# Template register map
Vendor: VendorName Co.Ltd; Series: SeriesName; File version: 1.2
CPU: CM7 r0p1, little endian, MPU, FPU, 4 interrupt priority bits
Registers are 32-bit, read-write, no defined reset value unless marked. A register's access mark holds for its fields unless they carry their own. Offsets are from the block's base; [hi:lo] are bit positions; {n}, {i} and the like mark numbered series.

## DCC1 — Dual-Clock Comparator
Base 0x40059000
Same registers: DCC2 0x4006B000, DCC3 0x4006C000
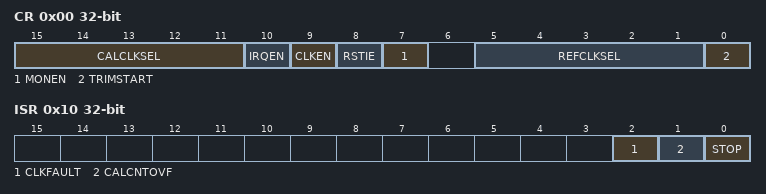
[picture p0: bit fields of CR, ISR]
0x00 CR — DCC config register
  [15:11] CALCLKSEL — DCC CALCLKSEL[4:0] bit: selection of clock source to be monitored
  [10] IRQEN — DCC IRQEN bit: interrupt enable
  [9] CLKEN — DCC CLKEN bit: clock enable
  [8] RSTIE — DCC RSTIE bit: reset or interrupt mode
  [7] MONEN — DCC MONEN bit: monitor mode enable
  [5:1] REFCLKSEL — DCC REFCLKSEL[4:0] bit: reference clock select
  [0] TRIMSTART — DCC TRIMSTART bit: soft monitor start
0x04 REFCON — DCC reference counter initial value config register
  [31:0] RCNTVAL — DCC RCNTVAL[31:0] bit: reference counter initial value
0x08 REFCNT ro — DCC reference counter value register
  [31:0] REFCNT — DCC REFCNT[31:0] bit: reference counter value
0x0C CALCNT ro — DCC calibrate counter value register
  [31:0] CALCNT — DCC CALCNT[31:0] bit: calibrated counter value
0x10 ISR ro — DCC interrupt flag register
  [2] CLKFAULT — DCC CLKFAULT bit: clock monitor fault flag
  [1] CALCNTOVF — DCC CALCNTOVF bit: calibration counter overflow flag
  [0] STOP — DCC STOP bit: reference counter stop flag
0x14 ICR wo — DCC interrupt flag clear register
  [2] CLKFAULT — DCC CLKFAULT bit: clear CLK_FAULT fault falg
0x1C HTCR — DCC clock monintor higher threshold comparison register
  [31:0] HTCR — DCC HTCR[31:0] bit: higher threshold compare
0x20 LTCR — DCC clock monintor lower threshold comparison register
  [31:0] LTCR — DCC LTCR[31:0] bit: low threshold compare

## DMAMUX1 — Direct Memory Access Multiplexer 1
Base 0x400B4000
Same registers: DMAMUX2 0x40093000
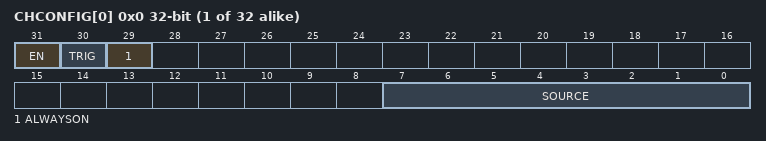
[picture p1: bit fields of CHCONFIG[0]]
{0x0+4i} CHCONFIG[{i}] (i=0..31) — Grouping of CHCONFIG
  [31] EN — DMAMUX EN bit: DMA mux channel enable
  [30] TRIG — DMAMUX TRIG bit: DMA channel trigger enable
  [29] ALWAYSON — DMAMUX ALWAYSON bit: DMA channel always enable
  [7:0] SOURCE — DMAMUX SOURCE[7:0] bit: DMA channel source

## EXTI — Extended Interrupt And Event Controller
Base 0x400C4000
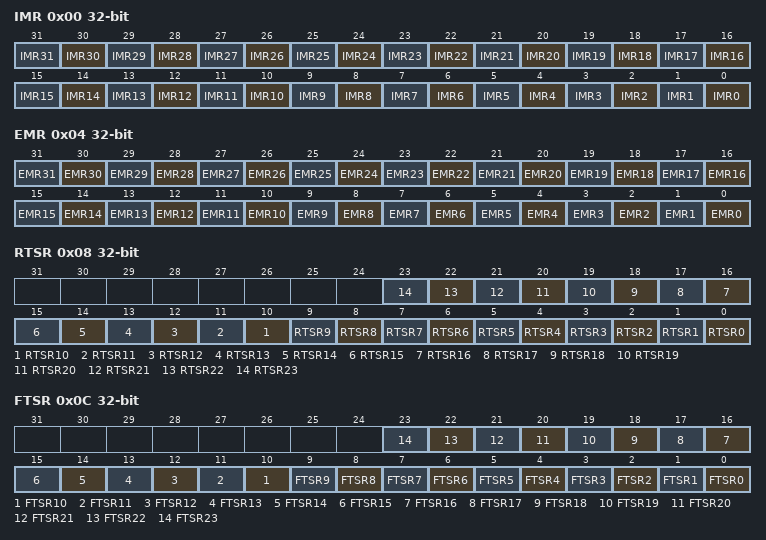
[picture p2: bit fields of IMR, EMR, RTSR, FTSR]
0x00 IMR — EXTI interrupt masking register
  [n] IMR{n} (n=24..31) — EXTI IMR{n} bit: direct event input {n}'s interrupt wakeup mask
  [n] IMR{n} (n=0..23) — EXTI IMR{n} bit: configurable event input {n}'s interrupt wakeup mask
0x04 EMR — EXTI event masking register
  [n] EMR{n} (n=24..31) — EXTI EMR{n} bit: direct event input {n}'s event wakeup mask
  [n] EMR{n} (n=0..23) — EXTI EMR{n} bit: configurable event input {n}'s event wakeup mask
0x08 RTSR — EXTI rising edge trigger selection register
  [n] RTSR{n} (n=0..23) — EXTI RTSR{n} bit: configurable event input {n}'s rising edge trigger configuration
0x0C FTSR — EXTI falling edge trigger selection register
  [n] FTSR{n} (n=0..23) — EXTI FTSR{n} bit: configurable event input {n}'s falling edge trigger configuration
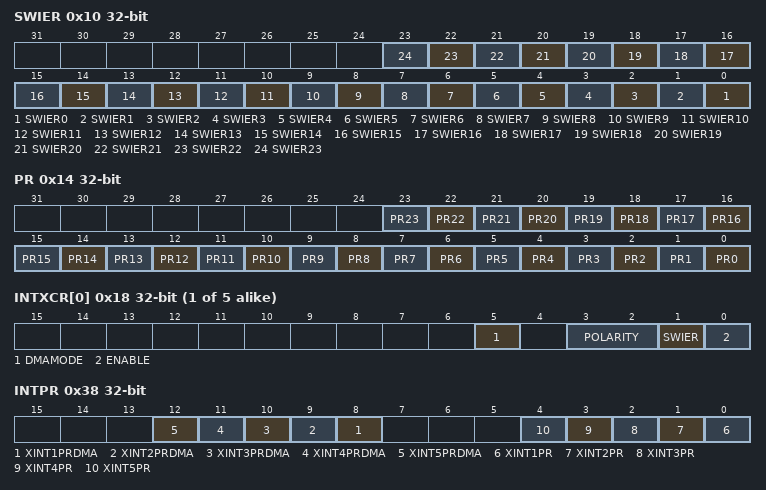
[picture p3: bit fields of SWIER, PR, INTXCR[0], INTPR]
0x10 SWIER — EXTI interrupt or event with software register
  [n] SWIER{n} (n=0..23) — EXTI SWIER{n} bit: configurable event input {n}'s software trigger interrupt or event configuration
0x14 PR — EXTI pendging register
  [n] PR{n} (n=0..23) — EXTI PR{n} bit: configurable event input {n}'s pending interrupt flag
{0x18+4i} INTXCR[{i}] (i=0..4) — Grouping of INT1CR~INT5CR
  [5] DMAMODE — EXTI DMAMODE bit: DMA request enable bit x
  [3:2] POLARITY — EXTI POLARITY[1:0] bit: edge-trigger interrupt type select x
  [1] SWIER wo — EXTI SWIER bit: XINT software trigger bit x
  [0] ENABLE — EXTI ENABLE bit: XINT interrupt enable x
{0x2C+4i} INTXCNTR[{i}] (i=0..2) ro — Grouping of INT1CNTR~INT3CNTR
  [15:0] CNTR — EXTI CNTR[15:0] bit: 16 bits count-up counter x
0x38 INTPR — EXTI XINT pending register
  [n+7] XINT{n}PRDMA (n=1..5) — EXTI XINT{n}PRDMA bit: XINT{n} DMA pending flag
  [n-1] XINT{n}PR (n=1..5) — EXTI XINT{n}PR bit: XINT{n} pending flag
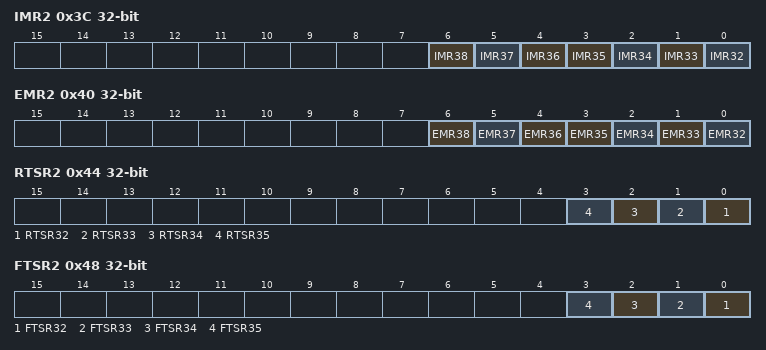
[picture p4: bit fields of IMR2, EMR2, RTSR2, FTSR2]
0x3C IMR2 — EXTI interrupt masking register 2
  [6] IMR38 — EXTI IMR38 bit: direct event input 38's interrupt wakeup mask
  [5] IMR37 — EXTI IMR37 bit: direct event input 37's interrupt wakeup mask
  [4] IMR36 — EXTI IMR36 bit: direct event input 36's interrupt wakeup mask
  [n-32] IMR{n} (n=32..35) — EXTI IMR{n} bit: configurable event input {n}'s interrupt wakeup mask
0x40 EMR2 — EXTI event masking register 2
  [6] EMR38 — EXTI EMR38 bit: direct event input 38's event wakeup mask
  [5] EMR37 — EXTI EMR37 bit: direct event input 37's event wakeup mask
  [4] EMR36 — EXTI EMR36 bit: direct event input 36's event wakeup mask
  [n-32] EMR{n} (n=32..35) — EXTI EMR{n} bit: configurable event input {n}'s event wakeup mask
0x44 RTSR2 — EXTI rising edge trigger selection register 2
  [n-32] RTSR{n} (n=32..35) — EXTI RTSR{n} bit: configurable event input {n}'s rising edge trigger configuration
0x48 FTSR2 — EXTI falling edge trigger selection register 2
  [n-32] FTSR{n} (n=32..35) — EXTI FTSR{n} bit: configurable event input {n}'s falling edge trigger configuration
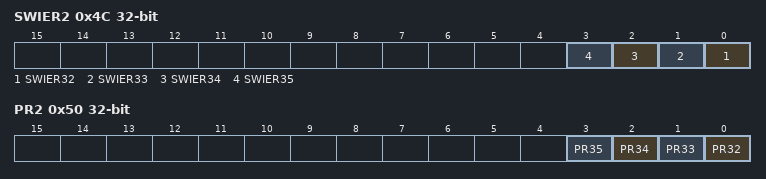
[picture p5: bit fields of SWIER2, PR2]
0x4C SWIER2 — EXTI interrupt or event with software register 2
  [n-32] SWIER{n} (n=32..35) — EXTI SWIER{n} bit: configurable event input {n}'s software trigger interrupt or event configuration
0x50 PR2 — EXTI XINT pendging register 2
  [n-32] PR{n} (n=32..35) — EXTI PR{n} bit: configurable event input {n}'s pending interrupt flag
